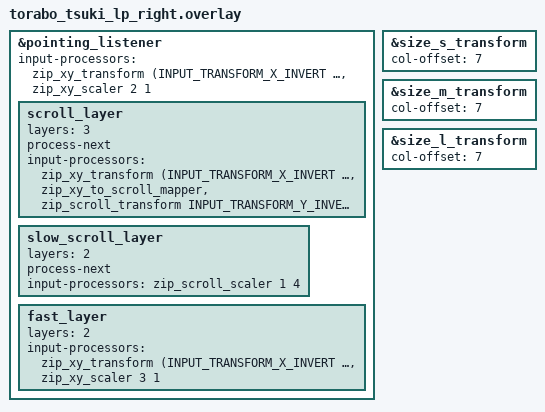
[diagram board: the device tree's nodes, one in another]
#include "torabo_tsuki_lp.dtsi"
#include <input/processors.dtsi>
#include <dt-bindings/zmk/input_transform.h>

&pointing_listener {
    input-processors =
        <&zip_xy_transform (INPUT_TRANSFORM_X_INVERT | INPUT_TRANSFORM_Y_INVERT)>,
        <&zip_xy_scaler 2 1>;

    scroll_layer {
        layers = <3>;
        process-next;
        input-processors =
            <&zip_xy_transform (INPUT_TRANSFORM_X_INVERT | INPUT_TRANSFORM_Y_INVERT)>,
            <&zip_xy_to_scroll_mapper>,
            <&zip_scroll_transform INPUT_TRANSFORM_Y_INVERT>;
    };

    slow_scroll_layer {
        layers = <2>;
        process-next;
        input-processors =
            <&zip_scroll_scaler 1 4>;
    };

    fast_layer {
        layers = <2>;
        input-processors =
            <&zip_xy_transform (INPUT_TRANSFORM_X_INVERT | INPUT_TRANSFORM_Y_INVERT)>,
            <&zip_xy_scaler 3 1>;
    };
};

&size_s_transform {
    col-offset = <7>;
};

&size_m_transform {
    col-offset = <7>;
};

&size_l_transform {
    col-offset = <7>;
};
